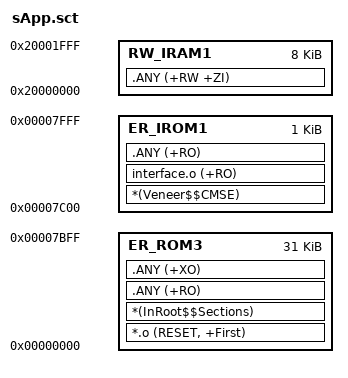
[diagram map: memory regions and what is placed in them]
; *************************************************************
; *** Scatter-Loading Description File generated by uVision ***
; *************************************************************

LR_ROM3 0x00000000 0x00007C00  {    ; load region size_region
  ER_ROM3 0x00000000 0x00007C00  {  ; load address = execution address
   *.o (RESET, +First)
   *(InRoot$$Sections)

   .ANY (+RO)
   .ANY (+XO)
  }
  RW_IRAM1 0x20000000 0x00002000  {  ; RW data
   .ANY (+RW +ZI)
  }
}

LR_IROM1 0x00007C00 0x00000400  {
  ER_IROM1 0x00007C00 0x00000400  {  ; load address = execution address
    *(Veneer$$CMSE)                   ; check with *_UROW.s
    interface.o (+RO)
   .ANY (+RO)
  }
}
